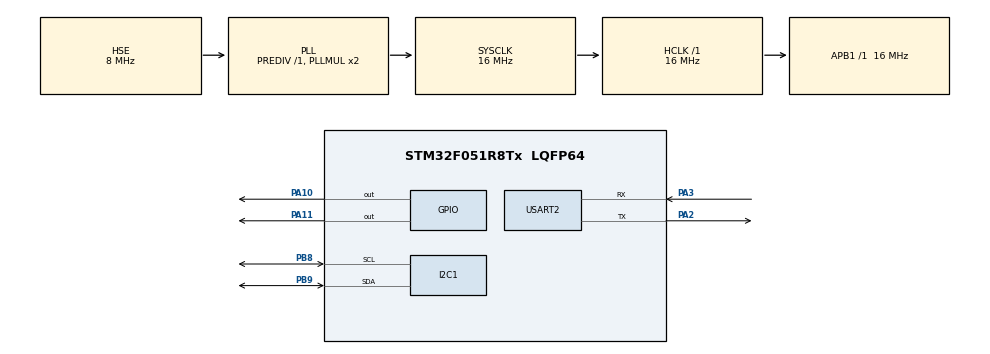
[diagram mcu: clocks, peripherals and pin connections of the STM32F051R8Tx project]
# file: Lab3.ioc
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Mcu.Family=STM32F0
Mcu.Name=STM32F051R8Tx
Mcu.Package=LQFP64
NVIC.TIM6_DAC_IRQn=true\:0\:0\:false\:false\:true\:true\:true
NVIC.USART2_IRQn=true\:0\:0\:false\:false\:true\:true\:true
PA10.Signal=GPIO_Output
PA11.Signal=GPIO_Output
PA2.Mode=Asynchronous
PA2.Signal=USART2_TX
PA3.Mode=Asynchronous
PA3.Signal=USART2_RX
PB8.Mode=I2C
PB8.Signal=I2C1_SCL
PB9.Mode=I2C
PB9.Signal=I2C1_SDA
PF0-OSC_IN.Mode=HSE-External-Clock-Source
PF0-OSC_IN.Signal=RCC_OSC_IN
ProjectManager.HeapSize=0x200
ProjectManager.StackSize=0x400
ProjectManager.TargetToolchain=MDK-ARM V5.27
RCC.AHBFreq_Value=16000000
RCC.APB1Freq_Value=16000000
RCC.APB1TimFreq_Value=16000000
RCC.HCLKFreq_Value=16000000
RCC.PLLSourceVirtual=RCC_PLLSOURCE_HSE
RCC.SYSCLKFreq_VALUE=16000000
RCC.SYSCLKSource=RCC_SYSCLKSOURCE_PLLCLK
TIM6.Period=10000
TIM6.Prescaler=480
USART2.VirtualMode-Asynchronous=VM_ASYNC
VP_TIM6_VS_ClockSourceINT.Mode=Enable_Timer
board=custom

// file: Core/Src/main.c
/* USER CODE BEGIN Header */
/**
  ******************************************************************************
  * @file           : main.c
  * @brief          : Main program body
  ******************************************************************************
  * @attention
  *
  * <h2><center>&copy; Copyright (c) 2021 STMicroelectronics.
  * All rights reserved.</center></h2>
  *
  * This software component is licensed by ST under BSD 3-Clause license,
  * the "License"; You may not use this file except in compliance with the
  * License. You may obtain a copy of the License at:
  *                        opensource.org/licenses/BSD-3-Clause
  *
  ******************************************************************************
  */
/* USER CODE END Header */
#include "main.h"
#include "stm32_tm1637.h"
#include "bmp280.h"

I2C_HandleTypeDef hi2c1;
int temperature[] = {0};
int preasure[] = {0};
TIM_HandleTypeDef htim6;

UART_HandleTypeDef huart2;

void SystemClock_Config(void);
static void MX_GPIO_Init(void);
static void MX_I2C1_Init(void);
static void MX_TIM6_Init(void);
static void MX_USART2_UART_Init(void);

int main(void)
{

  /* MCU Configuration--------------------------------------------------------*/

  /* Reset of all peripherals, Initializes the Flash interface and the Systick. */
  HAL_Init();

  /* Configure the system clock */
  SystemClock_Config();

  /* Initialize all configured peripherals */
  MX_GPIO_Init();
  MX_I2C1_Init();
  MX_TIM6_Init();
  MX_USART2_UART_Init();
	BMP280_Init();
  /* USER CODE BEGIN 2 */
HAL_TIM_Base_Start_IT(&htim6);
HAL_TIM_Base_Start(&htim6);
  /* USER CODE END 2 */
tm1637SetBrightness(5);
char str[100];
  /* Infinite loop */
  while (1)
  {
		sprintf(str, "Temperature: %d *C\r\nPressure: %d mmHg\r\n\n", temperature[0],preasure[0]);
		HAL_UART_Transmit_IT(&huart2,(uint8_t*)str,strlen(str));
tm1637DisplayDecimal(temperature[0],0);
		HAL_Delay(2000);
		tm1637DisplayDecimal(preasure[0],0);
		HAL_Delay(2000);

  }
}

void SystemClock_Config(void)
{
  RCC_OscInitTypeDef RCC_OscInitStruct = {0};
  RCC_ClkInitTypeDef RCC_ClkInitStruct = {0};
  RCC_PeriphCLKInitTypeDef PeriphClkInit = {0};

  /** Initializes the RCC Oscillators according to the specified parameters
  * in the RCC_OscInitTypeDef structure.
  */
  RCC_OscInitStruct.OscillatorType = RCC_OSCILLATORTYPE_HSI|RCC_OSCILLATORTYPE_HSE;
  RCC_OscInitStruct.HSEState = RCC_HSE_BYPASS;
  RCC_OscInitStruct.HSIState = RCC_HSI_ON;
  RCC_OscInitStruct.HSICalibrationValue = RCC_HSICALIBRATION_DEFAULT;
  RCC_OscInitStruct.PLL.PLLState = RCC_PLL_ON;
  RCC_OscInitStruct.PLL.PLLSource = RCC_PLLSOURCE_HSE;
  RCC_OscInitStruct.PLL.PLLMUL = RCC_PLL_MUL2;
  RCC_OscInitStruct.PLL.PREDIV = RCC_PREDIV_DIV1;
  if (HAL_RCC_OscConfig(&RCC_OscInitStruct) != HAL_OK)
  {
    Error_Handler();
  }
  /** Initializes the CPU, AHB and APB buses clocks
  */
  RCC_ClkInitStruct.ClockType = RCC_CLOCKTYPE_HCLK|RCC_CLOCKTYPE_SYSCLK
                              |RCC_CLOCKTYPE_PCLK1;
  RCC_ClkInitStruct.SYSCLKSource = RCC_SYSCLKSOURCE_PLLCLK;
  RCC_ClkInitStruct.AHBCLKDivider = RCC_SYSCLK_DIV1;
  RCC_ClkInitStruct.APB1CLKDivider = RCC_HCLK_DIV1;

  if (HAL_RCC_ClockConfig(&RCC_ClkInitStruct, FLASH_LATENCY_0) != HAL_OK)
  {
    Error_Handler();
  }
  PeriphClkInit.PeriphClockSelection = RCC_PERIPHCLK_I2C1;
  PeriphClkInit.I2c1ClockSelection = RCC_I2C1CLKSOURCE_HSI;
  if (HAL_RCCEx_PeriphCLKConfig(&PeriphClkInit) != HAL_OK)
  {
    Error_Handler();
  }
}

static void MX_I2C1_Init(void)
{

  hi2c1.Instance = I2C1;
  hi2c1.Init.Timing = 0x2000090E;
  hi2c1.Init.OwnAddress1 = 0;
  hi2c1.Init.AddressingMode = I2C_ADDRESSINGMODE_7BIT;
  hi2c1.Init.DualAddressMode = I2C_DUALADDRESS_DISABLE;
  hi2c1.Init.OwnAddress2 = 0;
  hi2c1.Init.OwnAddress2Masks = I2C_OA2_NOMASK;
  hi2c1.Init.GeneralCallMode = I2C_GENERALCALL_DISABLE;
  hi2c1.Init.NoStretchMode = I2C_NOSTRETCH_DISABLE;
  if (HAL_I2C_Init(&hi2c1) != HAL_OK)
  {
    Error_Handler();
  }
  /** Configure Analogue filter
  */
  if (HAL_I2CEx_ConfigAnalogFilter(&hi2c1, I2C_ANALOGFILTER_ENABLE) != HAL_OK)
  {
    Error_Handler();
  }
  /** Configure Digital filter
  */
  if (HAL_I2CEx_ConfigDigitalFilter(&hi2c1, 0) != HAL_OK)
  {
    Error_Handler();
  }

}

static void MX_TIM6_Init(void)
{

  TIM_MasterConfigTypeDef sMasterConfig = {0};

  htim6.Instance = TIM6;
  htim6.Init.Prescaler = 480;
  htim6.Init.CounterMode = TIM_COUNTERMODE_UP;
  htim6.Init.Period = 10000;
  htim6.Init.AutoReloadPreload = TIM_AUTORELOAD_PRELOAD_DISABLE;
  if (HAL_TIM_Base_Init(&htim6) != HAL_OK)
  {
    Error_Handler();
  }
  sMasterConfig.MasterOutputTrigger = TIM_TRGO_RESET;
  sMasterConfig.MasterSlaveMode = TIM_MASTERSLAVEMODE_DISABLE;
  if (HAL_TIMEx_MasterConfigSynchronization(&htim6, &sMasterConfig) != HAL_OK)
  {
    Error_Handler();
  }

}

static void MX_USART2_UART_Init(void)
{

  huart2.Instance = USART2;
  huart2.Init.BaudRate = 38400;
  huart2.Init.WordLength = UART_WORDLENGTH_8B;
  huart2.Init.StopBits = UART_STOPBITS_1;
  huart2.Init.Parity = UART_PARITY_NONE;
  huart2.Init.Mode = UART_MODE_TX_RX;
  huart2.Init.HwFlowCtl = UART_HWCONTROL_NONE;
  huart2.Init.OverSampling = UART_OVERSAMPLING_16;
  huart2.Init.OneBitSampling = UART_ONE_BIT_SAMPLE_DISABLE;
  huart2.AdvancedInit.AdvFeatureInit = UART_ADVFEATURE_NO_INIT;
  if (HAL_UART_Init(&huart2) != HAL_OK)
  {
    Error_Handler();
  }

}

static void MX_GPIO_Init(void)
{
  GPIO_InitTypeDef GPIO_InitStruct = {0};

  /* GPIO Ports Clock Enable */
  __HAL_RCC_GPIOF_CLK_ENABLE();
  __HAL_RCC_GPIOA_CLK_ENABLE();
  __HAL_RCC_GPIOB_CLK_ENABLE();

  /*Configure GPIO pin Output Level */
  HAL_GPIO_WritePin(GPIOA, GPIO_PIN_10|GPIO_PIN_11, GPIO_PIN_RESET);

  /*Configure GPIO pins : PA10 PA11 */
  GPIO_InitStruct.Pin = GPIO_PIN_10|GPIO_PIN_11;
  GPIO_InitStruct.Mode = GPIO_MODE_OUTPUT_PP;
  GPIO_InitStruct.Pull = GPIO_NOPULL;
  GPIO_InitStruct.Speed = GPIO_SPEED_FREQ_LOW;
  HAL_GPIO_Init(GPIOA, &GPIO_InitStruct);

}

void Error_Handler(void)
{
  __disable_irq();
  while (1)
  {
  }
}

/************************ (C) COPYRIGHT STMicroelectronics *****END OF FILE****/
